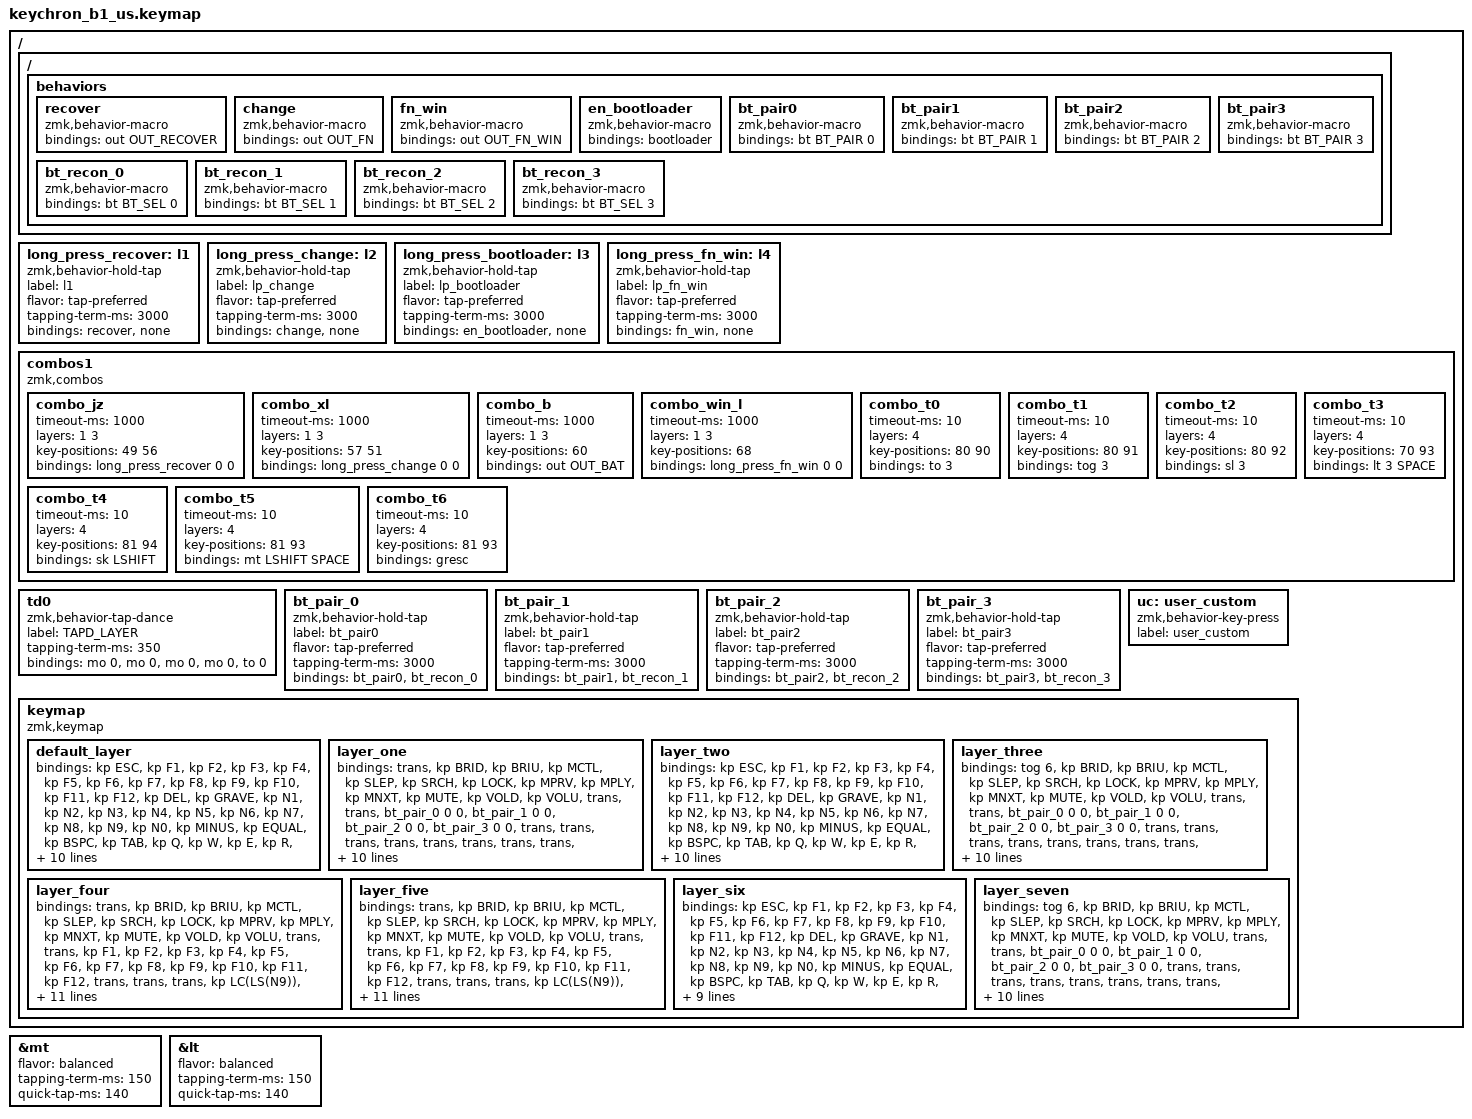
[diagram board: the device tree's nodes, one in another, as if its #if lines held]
/*
 * Copyright (c) 2023 The ZMK Contributors
 *
 * SPDX-License-Identifier: MIT
 */

#include <behaviors.dtsi>
#include <dt-bindings/zmk/keys.h>
#include <dt-bindings/zmk/rgb.h>
#include <dt-bindings/zmk/bt.h>
#include <dt-bindings/zmk/outputs.h>

#define BRID C_BRI_DN
#define BRIU C_BRI_UP
#define MCTL C_AC_DESKTOP_SHOW_ALL_WINDOWS
#define SLEP C_SLEEP
#define SRCH C_AC_SEARCH
#define LOCK C_AL_LOCK
#define MPRV C_PREV
#define MPLY C_PP
#define MNXT C_NEXT
#define MUTE C_MUTE
#ifdef VOLD
    #undef VOLD
    #define VOLD C_VOL_DN
#endif
#ifdef VOLU
    #undef VOLU
    #define VOLU C_VOL_UP
#endif

&mt {
    flavor = "balanced";
    tapping-term-ms = <150>;
    quick-tap-ms = <140>;
};

&lt {
    flavor = "balanced";
    tapping-term-ms = <150>;
    quick-tap-ms = <140>;
};

/ {
    ZMK_MACRO(recover, bindings = <&out OUT_RECOVER>;)
    ZMK_MACRO(change, bindings = <&out OUT_FN>;)
    ZMK_MACRO(fn_win, bindings = <&out OUT_FN_WIN>;)

    ZMK_MACRO(en_bootloader, bindings = <&bootloader>;)
    ZMK_MACRO1(MA,bindings=<&kp 0x770000>;)

    long_press_recover:l1 {
        compatible = "zmk,behavior-hold-tap";
        label = "l1";
        #binding-cells = <2>;
        flavor = "tap-preferred";
        tapping-term-ms = <3000>;  // delay amount in ms
        bindings = <&recover>, <&none>;
    };

    long_press_change:l2{
        compatible = "zmk,behavior-hold-tap";
        label = "lp_change";
        #binding-cells = <2>;
        flavor = "tap-preferred";
        tapping-term-ms = <3000>;  // delay amount in ms
        bindings = <&change>, <&none>;
    };
    long_press_bootloader:l3{
        compatible = "zmk,behavior-hold-tap";
        label = "lp_bootloader";
        #binding-cells = <2>;
        flavor = "tap-preferred";
        tapping-term-ms = <3000>;  // delay amount in ms
        bindings = <&en_bootloader>, <&none>;
    };
    long_press_fn_win:l4{
        compatible = "zmk,behavior-hold-tap";
        label = "lp_fn_win";
        #binding-cells = <2>;
        flavor = "tap-preferred";
        tapping-term-ms = <3000>;   
        bindings = <&fn_win>, <&none>;
    };
   

    combos1 {
        compatible = "zmk,combos";
        combo_jz {
            timeout-ms = <1000>;
            layers = <1 3>;
            key-positions = <49 56>; //fn+j+z
            bindings = <&long_press_recover 0 0>;
        };
        combo_xl {
            timeout-ms = <1000>;
            layers =< 1 3>;
            key-positions = <57 51>; //fn+x+l
            bindings = <&long_press_change 0 0>;
        };
        combo_b {
            timeout-ms = <1000>;
            layers =< 1 3>;
            //slow-release = <true>;
            key-positions = <60>; //fn+b
            bindings = <&out OUT_BAT>;
        };

        combo_win_l {
            timeout-ms = <1000>;
            layers =< 1 3>;
            //slow-release = <true>;
            key-positions = <68>; //fn+win
            bindings = <&long_press_fn_win 0 0>;
        };

        combo_t0 {
            timeout-ms = <10 >;
            layers =<4>;
          
            key-positions = <80 90>;  
            bindings = <&to 3 >;
        };
        combo_t1 {
            timeout-ms = <10 >;
            layers =<4>;
          
            key-positions = <80 91>;  
            bindings = <&tog 3 >;
        };
        combo_t2 {
            timeout-ms = <10 >;
            layers =<4>;
          
            key-positions = <80 92>;  
            bindings = <&sl 3 >;
        };
        combo_t3 {
            timeout-ms = <10 >;
            layers =<4>;
          
            key-positions = <70 93>;  
            bindings = <&lt 3 SPACE>;
        };
        combo_t4 {
            timeout-ms = <10 >;
            layers =<4>;
          
            key-positions = <81 94>;  
            bindings = <&sk LSHIFT>;
        };
        combo_t5 {
            timeout-ms = <10 >;
            layers =<4>;
          
            key-positions = <81 93>;  
            bindings = <&mt LSHIFT SPACE>;
        };
        combo_t6 {
            timeout-ms = <10 >;
            layers =<4>;
          
            key-positions = <81 93>;  
            bindings = <&gresc>;
        };
    };

    td0 {
        compatible = "zmk,behavior-tap-dance";
        label = "TAPD_LAYER";
        #binding-cells = <1>;
        tapping-term-ms = <350>;
        bindings =<&mo 0>,<&mo 0>,<&mo 0>,<&mo 0>,<&to 0>;
    };
    ZMK_MACRO(bt_pair0, bindings = <&bt BT_PAIR 0>;)
    ZMK_MACRO(bt_pair1, bindings = <&bt BT_PAIR 1>;)
    ZMK_MACRO(bt_pair2, bindings = <&bt BT_PAIR 2>;)
    ZMK_MACRO(bt_pair3, bindings = <&bt BT_PAIR 3>;)
    ZMK_MACRO(bt_recon_0, bindings = <&bt BT_SEL 0>;)
    ZMK_MACRO(bt_recon_1, bindings = <&bt BT_SEL 1>;)
    ZMK_MACRO(bt_recon_2, bindings = <&bt BT_SEL 2>;)
    ZMK_MACRO(bt_recon_3, bindings = <&bt BT_SEL 3>;)
    


    bt_pair_0: bt_pair_0 {
        compatible = "zmk,behavior-hold-tap";
        label = "bt_pair0";
        #binding-cells = <2>;
        flavor = "tap-preferred";
        tapping-term-ms = <3000>;  // delay amount in ms
        bindings = <&bt_pair0>, <&bt_recon_0>;
    };
    bt_pair_1: bt_pair_1 {
        compatible = "zmk,behavior-hold-tap";
        label = "bt_pair1";
        #binding-cells = <2>;
        flavor = "tap-preferred";
        tapping-term-ms = <3000>;  // delay amount in ms
        bindings = <&bt_pair1>, <&bt_recon_1>;
    };
    bt_pair_2: bt_pair_2 {
        compatible = "zmk,behavior-hold-tap";
        label = "bt_pair2";
        #binding-cells = <2>;
        flavor = "tap-preferred";
        tapping-term-ms = <3000>;  // delay amount in ms
        bindings = <&bt_pair2>, <&bt_recon_2>;
    };
    bt_pair_3: bt_pair_3 {
        compatible = "zmk,behavior-hold-tap";
        label = "bt_pair3";
        #binding-cells = <2>;
        flavor = "tap-preferred";
        tapping-term-ms = <3000>;  // delay amount in ms
        bindings = <&bt_pair3>, <&bt_recon_3>;
    };
    uc:user_custom {
        compatible = "zmk,behavior-key-press";
        label ="user_custom";
        #binding-cells =<1>;
    };

	keymap {
    	compatible = "zmk,keymap";
        //mac
        default_layer {
        bindings = <
            &kp ESC     &kp F1      &kp F2      &kp F3      &kp F4      &kp F5      &kp F6      &kp F7      &kp F8      &kp F9      &kp F10     &kp F11     &kp F12     &kp DEL
            &kp GRAVE   &kp N1      &kp N2      &kp N3      &kp N4      &kp N5      &kp N6      &kp N7      &kp N8      &kp N9      &kp N0      &kp MINUS   &kp EQUAL   &kp BSPC
            &kp TAB     &kp Q       &kp W       &kp E       &kp R       &kp T       &kp Y       &kp U       &kp I       &kp O       &kp P       &kp LBKT    &kp RBKT    &kp BSLH
            &lt 4 CLCK  &kp A       &mt LCTL S  &mt LGUI D  &mt LALT F  &kp G       &kp H       &mt RALT J  &mt RGUI K  &mt RCTL L  &kp SEMI    &kp SQT                 &kp RET
            &kp LSHFT   &kp Z       &kp X       &kp C       &kp V       &kp B       &kp N       &kp M       &kp COMMA   &kp DOT     &kp FSLH                            &kp RSHFT
            &kp LCTRL   &uc LGUI    &uc LALT                                &kp SPACE                       &uc RALT    &mo 1       &kp LEFT    &kp UP      &kp DOWN    &kp RIGHT
            &mo 2       &out OUT_BLE            &out OUT_24G            &out OUT_CHG            &out OUT_CHGD
        >;
        };
        //mac
        layer_one  {
        bindings = < 
            &trans      &kp BRID            &kp BRIU        &kp MCTL        &kp SLEP        &kp SRCH        &kp LOCK        &kp MPRV    &kp MPLY    &kp MNXT        &kp MUTE        &kp VOLD    &kp VOLU    &trans
            &trans      &bt_pair_0 0 0      &bt_pair_1 0 0  &bt_pair_2 0 0  &bt_pair_3 0 0  &trans          &trans          &trans      &trans      &trans          &trans          &trans      &trans      &trans
            &trans      &trans              &trans          &trans          &trans          &trans          &trans          &trans      &trans      &trans          &trans          &trans      &trans      &trans
            &trans      &trans              &trans          &trans          &trans          &trans          &trans          &trans      &trans      &trans          &trans          &trans                  &trans      
            &trans      &trans              &trans          &trans          &trans          &trans          &trans          &trans      &trans      &trans          &trans                                  &trans 
            &bootloader &trans              &trans                                              &trans                                  &trans      &trans          &trans          &trans      &trans      &trans   
            &none       &none               &none           &none            &none 
        >;
        };
        //unix
        layer_two {
 		bindings = <
            &kp ESC     &kp F1      &kp F2      &kp F3      &kp F4      &kp F5      &kp F6      &kp F7      &kp F8      &kp F9      &kp F10     &kp F11     &kp F12     &kp DEL
            &kp GRAVE   &kp N1      &kp N2      &kp N3      &kp N4      &kp N5      &kp N6      &kp N7      &kp N8      &kp N9      &kp N0      &kp MINUS   &kp EQUAL   &kp BSPC
            &kp TAB     &kp Q       &kp W       &kp E       &kp R       &kp T       &kp Y       &kp U       &kp I       &kp O       &kp P       &kp LBKT    &kp RBKT    &kp BSLH
            &lt 5 CLCK  &kp A       &mt LCTL S  &mt LGUI D  &mt LALT F  &kp G       &kp H       &mt RALT J  &mt RGUI K  &mt RCTL L  &kp SEMI    &kp SQT                 &kp RET
            &kp LSHFT   &kp Z       &kp X       &kp C       &kp V       &kp B       &kp N       &kp M       &kp COMMA   &kp DOT     &kp FSLH                            &kp RSHFT
            &kp LCTRL   &uc LGUI    &uc LALT                                &kp SPACE                       &uc RALT    &mo 3       &kp LEFT    &kp UP      &kp DOWN    &kp RIGHT
            &mo 2       &out OUT_BLE            &out OUT_24G            &out OUT_CHG            &out OUT_CHGD
        >;
        };
        //unix
        layer_three {
        bindings = < 
            &tog 6      &kp BRID            &kp BRIU        &kp MCTL        &kp SLEP        &kp SRCH        &kp LOCK        &kp MPRV    &kp MPLY    &kp MNXT        &kp MUTE        &kp VOLD    &kp VOLU    &trans
            &trans      &bt_pair_0 0 0      &bt_pair_1 0 0  &bt_pair_2 0 0  &bt_pair_3 0 0  &trans          &trans          &trans      &trans      &trans          &trans          &trans      &trans      &trans
            &trans      &trans              &trans          &trans          &trans          &trans          &trans          &trans      &trans      &trans          &trans          &trans      &trans      &trans
            &trans      &trans              &trans          &trans          &trans          &trans          &trans          &trans      &trans      &trans          &trans          &trans                  &trans      
            &trans      &trans              &trans          &trans          &trans          &trans          &trans          &trans      &trans      &trans          &trans                                  &trans 
            &bootloader &trans              &trans                                              &trans                                  &trans      &trans          &trans          &trans      &trans      &trans   
            &none       &none               &none           &none            &none 
        >;
        };
        //lower
        layer_four {
        bindings = < 
            &trans      &kp BRID    &kp BRIU        &kp MCTL        &kp SLEP        &kp SRCH        &kp LOCK        &kp MPRV    &kp MPLY    &kp MNXT        &kp MUTE        &kp VOLD    &kp VOLU    &trans
            &trans      &kp F1      &kp F2          &kp F3          &kp F4          &kp F5          &kp F6          &kp F7      &kp F8      &kp F9          &kp F10         &kp F11     &kp F12     &trans
            &trans      &trans      &kp LC(LS(N9))  &kp LS(LEFT)    &kp LS(RIGHT)   &kp LC(LS(T))   &kp LA(LEFT)    &kp PG_DN   &kp PG_UP   &kp LA(RIGHT)   &kp LG(LS(N4))  &trans      &trans      &kp LC(RBKT)
            &trans      &trans      &trans          &kp LC(PG_UP)   &kp LC(PG_DN)   &trans          &kp LEFT        &kp DOWN    &kp UP      &kp RIGHT       &trans          &trans                  &trans      
            &trans      &trans      &trans          &trans          &kp LA(LCTL)    &trans          &trans          &kp END     &kp HOME    &kp DEL         &trans                                  &trans 
            &trans      &trans      &trans                                              &trans                                  &trans      &trans          &trans          &trans      &trans      &trans   
            &none       &none       &none           &none           &none 
        >;
        };
        //raise
        layer_five  {
        bindings = < 
            &trans      &kp BRID    &kp BRIU        &kp MCTL        &kp SLEP        &kp SRCH        &kp LOCK        &kp MPRV    &kp MPLY    &kp MNXT        &kp MUTE            &kp VOLD    &kp VOLU    &trans
            &trans      &kp F1      &kp F2          &kp F3          &kp F4          &kp F5          &kp F6          &kp F7      &kp F8      &kp F9          &kp F10             &kp F11     &kp F12     &trans
            &trans      &trans      &kp LC(LS(N9))  &kp LS(LEFT)    &kp LS(RIGHT)   &kp LC(LS(T))   &kp LC(LEFT)    &kp PG_DN   &kp PG_UP   &kp LC(RIGHT)   &kp LG(LS(PSCRN))   &trans      &trans      &kp LC(RBKT)
            &trans      &trans      &trans          &kp LC(PG_UP)   &kp LC(PG_DN)   &trans          &kp LEFT        &kp DOWN    &kp UP      &kp RIGHT       &trans              &trans                  &trans      
            &trans      &trans      &trans          &trans          &kp LA(LCTL)    &trans          &trans          &kp END     &kp HOME    &kp DEL         &trans                                      &trans 
            &trans      &trans      &trans                                              &trans                                  &trans      &trans          &trans              &trans      &trans      &trans   
            &none       &none       &none           &none           &none 
        >;
        };
        //win
        layer_six {
 		bindings = <
            &kp ESC     &kp F1      &kp F2      &kp F3      &kp F4      &kp F5      &kp F6      &kp F7      &kp F8      &kp F9      &kp F10     &kp F11     &kp F12     &kp DEL
            &kp GRAVE   &kp N1      &kp N2      &kp N3      &kp N4      &kp N5      &kp N6      &kp N7      &kp N8      &kp N9      &kp N0      &kp MINUS   &kp EQUAL   &kp BSPC
            &kp TAB     &kp Q       &kp W       &kp E       &kp R       &kp T       &kp Y       &kp U       &kp I       &kp O       &kp P       &kp LBKT    &kp RBKT    &kp BSLH
            &kp CLCK    &kp A       &kp S       &kp D       &kp F       &kp G       &kp H       &kp J       &kp K       &kp L       &kp SEMI    &kp SQT                 &kp RET
            &kp LSHFT   &kp Z       &kp X       &kp C       &kp V       &kp B       &kp N       &kp M       &kp COMMA   &kp DOT     &kp FSLH                            &kp RSHFT
            &kp LCTRL   &uc LGUI    &uc LALT                                &kp SPACE                       &uc RALT    &mo 7       &kp LEFT    &kp UP      &kp DOWN    &kp RIGHT
            &mo 2       &out OUT_BLE            &out OUT_24G            &out OUT_CHG            &out OUT_CHGD
        >;
        };
        //win_fn
        layer_seven {
        bindings = < 
            &tog 6      &kp BRID            &kp BRIU        &kp MCTL        &kp SLEP        &kp SRCH        &kp LOCK        &kp MPRV    &kp MPLY    &kp MNXT        &kp MUTE        &kp VOLD    &kp VOLU    &trans
            &trans      &bt_pair_0 0 0      &bt_pair_1 0 0  &bt_pair_2 0 0  &bt_pair_3 0 0  &trans          &trans          &trans      &trans      &trans          &trans          &trans      &trans      &trans
            &trans      &trans              &trans          &trans          &trans          &trans          &trans          &trans      &trans      &trans          &trans          &trans      &trans      &trans
            &trans      &trans              &trans          &trans          &trans          &trans          &trans          &trans      &trans      &trans          &trans          &trans                  &trans      
            &trans      &trans              &trans          &trans          &trans          &trans          &trans          &trans      &trans      &trans          &trans                                  &trans 
            &bootloader &trans              &trans                                              &trans                                  &trans      &trans          &trans          &trans      &trans      &trans   
            &none       &none               &none           &none            &none 
        >;
        };
   

    	
    
	};
};

	
